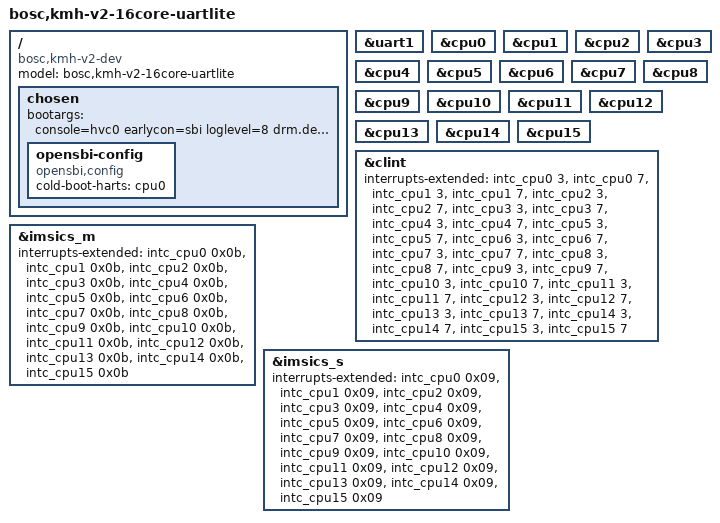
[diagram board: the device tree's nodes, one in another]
// SPDX-License-Identifier: (GPL-2.0 OR MIT)
/* Copyright (c) 2025 BOSC */

/dts-v1/;
#include "kmh-v2.dtsi"

/ {
	#address-cells = <2>;
	#size-cells = <2>;
	compatible = "bosc,kmh-v2-dev";
	model = "bosc,kmh-v2-16core-uartlite";

	chosen {
		bootargs = "console=hvc0 earlycon=sbi loglevel=8 drm.debug=0x2";
		opensbi-config {
		    compatible = "opensbi,config";
		    cold-boot-harts = <&cpu0>;
		};
	};
};

&uart1 {
	status = "okay";
};

&cpu0 {
	status = "okay";
};

&cpu1 {
	status = "okay";
};

&cpu2 {
	status = "okay";
};

&cpu3 {
	status = "okay";
};

&cpu4 {
	status = "okay";
};

&cpu5 {
	status = "okay";
};

&cpu6 {
	status = "okay";
};

&cpu7 {
	status = "okay";
};

&cpu8 {
	status = "okay";
};

&cpu9 {
	status = "okay";
};

&cpu10 {
	status = "okay";
};

&cpu11 {
	status = "okay";
};

&cpu12 {
	status = "okay";
};

&cpu13 {
	status = "okay";
};

&cpu14 {
	status = "okay";
};

&cpu15 {
	status = "okay";
};

&clint {
	interrupts-extended =
		<&intc_cpu0 3>, <&intc_cpu0 7>,
		<&intc_cpu1 3>, <&intc_cpu1 7>,
		<&intc_cpu2 3>, <&intc_cpu2 7>,
		<&intc_cpu3 3>, <&intc_cpu3 7>,
        <&intc_cpu4 3>, <&intc_cpu4 7>,
		<&intc_cpu5 3>, <&intc_cpu5 7>,
		<&intc_cpu6 3>, <&intc_cpu6 7>,
		<&intc_cpu7 3>, <&intc_cpu7 7>,
        <&intc_cpu8 3>, <&intc_cpu8 7>,
		<&intc_cpu9 3>, <&intc_cpu9 7>,
		<&intc_cpu10 3>, <&intc_cpu10 7>,
		<&intc_cpu11 3>, <&intc_cpu11 7>,
        <&intc_cpu12 3>, <&intc_cpu12 7>,
		<&intc_cpu13 3>, <&intc_cpu13 7>,
		<&intc_cpu14 3>, <&intc_cpu14 7>,
		<&intc_cpu15 3>, <&intc_cpu15 7>;
};

&imsics_m {
	interrupts-extended =
		<&intc_cpu0 0x0b>,
		<&intc_cpu1 0x0b>,
		<&intc_cpu2 0x0b>,
		<&intc_cpu3 0x0b>,
        <&intc_cpu4 0x0b>,
		<&intc_cpu5 0x0b>,
		<&intc_cpu6 0x0b>,
		<&intc_cpu7 0x0b>,
        <&intc_cpu8 0x0b>,
		<&intc_cpu9 0x0b>,
		<&intc_cpu10 0x0b>,
		<&intc_cpu11 0x0b>,
        <&intc_cpu12 0x0b>,
		<&intc_cpu13 0x0b>,
		<&intc_cpu14 0x0b>,
		<&intc_cpu15 0x0b>;
};

&imsics_s {
	interrupts-extended =
		<&intc_cpu0 0x09>,
		<&intc_cpu1 0x09>,
		<&intc_cpu2 0x09>,
		<&intc_cpu3 0x09>,
        <&intc_cpu4 0x09>,
		<&intc_cpu5 0x09>,
		<&intc_cpu6 0x09>,
		<&intc_cpu7 0x09>,
        <&intc_cpu8 0x09>,
		<&intc_cpu9 0x09>,
		<&intc_cpu10 0x09>,
		<&intc_cpu11 0x09>,
        <&intc_cpu12 0x09>,
		<&intc_cpu13 0x09>,
		<&intc_cpu14 0x09>,
		<&intc_cpu15 0x09>;
};
